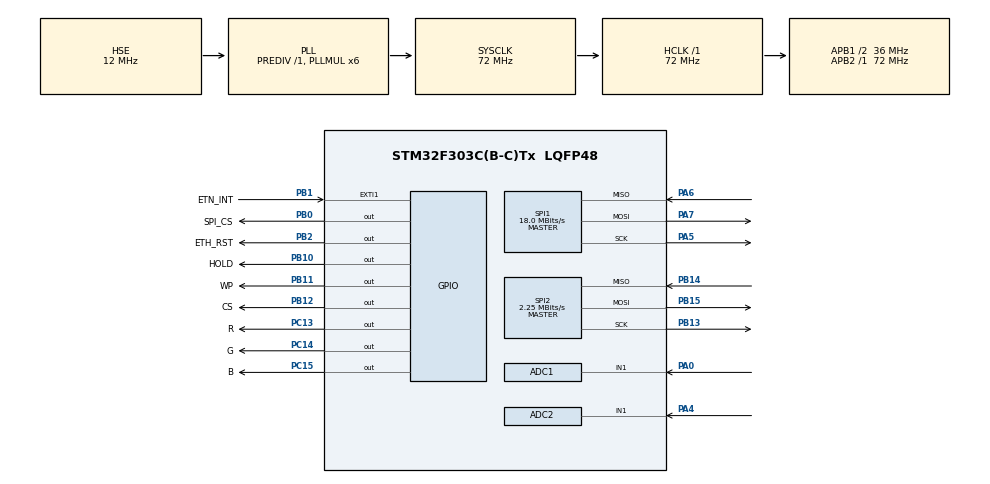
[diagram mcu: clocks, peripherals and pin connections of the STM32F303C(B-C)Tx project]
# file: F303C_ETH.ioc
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ADC1.Channel-0\#ChannelRegularConversion=ADC_CHANNEL_1
ADC1.ClockPrescaler=ADC_CLOCK_SYNC_PCLK_DIV2
ADC1.ContinuousConvMode=DISABLE
ADC1.DMAContinuousRequests=ENABLE
ADC1.ExternalTrigConv=ADC_EXTERNALTRIGCONV_T3_TRGO
ADC1.NbrOfConversionFlag=1
ADC1.Offset-0\#ChannelRegularConversion=0
ADC1.OffsetNumber-0\#ChannelRegularConversion=ADC_OFFSET_NONE
ADC1.Rank-0\#ChannelRegularConversion=1
ADC1.SamplingTime-0\#ChannelRegularConversion=ADC_SAMPLETIME_61CYCLES_5
ADC1.master=1
ADC2.Channel-0\#ChannelRegularConversion=ADC_CHANNEL_1
ADC2.ClockPrescaler=ADC_CLOCK_SYNC_PCLK_DIV2
ADC2.NbrOfConversionFlag=1
ADC2.Offset-0\#ChannelRegularConversion=0
ADC2.OffsetNumber-0\#ChannelRegularConversion=ADC_OFFSET_NONE
ADC2.Rank-0\#ChannelRegularConversion=1
ADC2.SamplingTime-0\#ChannelRegularConversion=ADC_SAMPLETIME_1CYCLE_5
Dma.ADC1.0.Direction=DMA_PERIPH_TO_MEMORY
Dma.ADC1.0.Instance=DMA1_Channel1
Dma.ADC1.0.MemDataAlignment=DMA_MDATAALIGN_HALFWORD
Dma.ADC1.0.MemInc=DMA_MINC_ENABLE
Dma.ADC1.0.Mode=DMA_CIRCULAR
Dma.ADC1.0.PeriphDataAlignment=DMA_PDATAALIGN_HALFWORD
Dma.ADC1.0.PeriphInc=DMA_PINC_DISABLE
Dma.ADC1.0.Priority=DMA_PRIORITY_LOW
Dma.Request0=ADC1
FREERTOS.BinarySemaphores01=ADC_end,Dynamic,NULL
FREERTOS.Tasks01=MainTask,0,256,mainTask,Default,NULL,Dynamic,NULL,NULL;LED,0,256,led,Default,NULL,Dynamic,NULL,NULL
FREERTOS.configTOTAL_HEAP_SIZE=10072
Mcu.Family=STM32F3
Mcu.Name=STM32F303C(B-C)Tx
Mcu.Package=LQFP48
NVIC.DMA1_Channel1_IRQn=true\:5\:0\:false\:false\:true\:true\:false\:true\:true
NVIC.PriorityGroup=NVIC_PRIORITYGROUP_4
NVIC.TIM6_DAC_IRQn=true\:5\:0\:false\:false\:true\:true\:true\:true\:true
NVIC.TIM7_IRQn=true\:0\:0\:false\:false\:true\:false\:false\:true\:true
NVIC.TimeBase=TIM7_IRQn
NVIC.TimeBaseIP=TIM7
PA0.Mode=IN1-Single-Ended
PA0.Signal=ADC1_IN1
PA13.Mode=Serial_Wire
PA13.Signal=SYS_JTMS-SWDIO
PA14.Mode=Serial_Wire
PA14.Signal=SYS_JTCK-SWCLK
PA4.Mode=IN1-Single-Ended
PA4.Signal=ADC2_IN1
PA5.Mode=Full_Duplex_Master
PA5.Signal=SPI1_SCK
PA6.Mode=Full_Duplex_Master
PA6.Signal=SPI1_MISO
PA7.Mode=Full_Duplex_Master
PA7.Signal=SPI1_MOSI
PB0.GPIO_Label=SPI_CS
PB0.Signal=GPIO_Output
PB1.GPIO_Label=ETN_INT
PB1.Signal=GPXTI1
PB10.GPIO_Label=HOLD
PB10.Signal=GPIO_Output
PB11.GPIO_Label=WP
PB11.Signal=GPIO_Output
PB12.GPIO_Label=CS
PB12.Signal=GPIO_Output
PB13.Mode=Full_Duplex_Master
PB13.Signal=SPI2_SCK
PB14.Mode=Full_Duplex_Master
PB14.Signal=SPI2_MISO
PB15.Mode=Full_Duplex_Master
PB15.Signal=SPI2_MOSI
PB2.GPIO_Label=ETH_RST
PB2.Signal=GPIO_Output
PC13.GPIO_Label=R
PC13.Signal=GPIO_Output
PC14-OSC32_IN.GPIO_Label=G
PC14-OSC32_IN.Signal=GPIO_Output
PC15-OSC32_OUT.GPIO_Label=B
PC15-OSC32_OUT.Signal=GPIO_Output
PF0-OSC_IN.Mode=HSE-External-Oscillator
PF0-OSC_IN.Signal=RCC_OSC_IN
PF1-OSC_OUT.Mode=HSE-External-Oscillator
PF1-OSC_OUT.Signal=RCC_OSC_OUT
ProjectManager.HeapSize=0x1770
ProjectManager.StackSize=0x2710
ProjectManager.TargetToolchain=STM32CubeIDE
RCC.AHBFreq_Value=72000000
RCC.APB1CLKDivider=RCC_HCLK_DIV2
RCC.APB1Freq_Value=36000000
RCC.APB1TimFreq_Value=72000000
RCC.APB2Freq_Value=72000000
RCC.APB2TimFreq_Value=72000000
RCC.CortexFreq_Value=72000000
RCC.HCLKFreq_Value=72000000
RCC.HSE_VALUE=12000000
RCC.HSI_VALUE=8000000
RCC.LSE_VALUE=32768
RCC.PLLMUL=RCC_PLL_MUL6
RCC.PLLSourceVirtual=RCC_PLLSOURCE_HSE
RCC.SYSCLKFreq_VALUE=72000000
RCC.SYSCLKSourceVirtual=RCC_SYSCLKSOURCE_PLLCLK
RCC.USBFreq_Value=72000000
SPI1.BaudRatePrescaler=SPI_BAUDRATEPRESCALER_4
SPI1.CalculateBaudRate=18.0 MBits/s
SPI1.DataSize=SPI_DATASIZE_8BIT
SPI1.Direction=SPI_DIRECTION_2LINES
SPI1.Mode=SPI_MODE_MASTER
SPI1.VirtualType=VM_MASTER
SPI2.BaudRatePrescaler=SPI_BAUDRATEPRESCALER_16
SPI2.CalculateBaudRate=2.25 MBits/s
SPI2.DataSize=SPI_DATASIZE_8BIT
SPI2.Direction=SPI_DIRECTION_2LINES
SPI2.Mode=SPI_MODE_MASTER
SPI2.VirtualType=VM_MASTER
TIM3.Channel-Output\ Compare1\ No\ Output=TIM_CHANNEL_1
TIM3.Period=1000-1
TIM3.Prescaler=72-1
TIM3.TIM_MasterOutputTrigger=TIM_TRGO_UPDATE
TIM6.Prescaler=72-1
VP_FREERTOS_VS_CMSIS_V1.Mode=CMSIS_V1
VP_SYS_VS_tim7.Mode=TIM7
VP_TIM3_VS_no_output1.Mode=Output Compare1 No Output
VP_TIM6_VS_ClockSourceINT.Mode=Enable_Timer
board=custom

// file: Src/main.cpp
/* USER CODE BEGIN Header */
/**
  ******************************************************************************
  * @file           : main.c
  * @brief          : Main program body
  ******************************************************************************
  * @attention
  *
  * Copyright (c) 2022 STMicroelectronics.
  * All rights reserved.
  *
  * This software is licensed under terms that can be found in the LICENSE file
  * in the root directory of this software component.
  * If no LICENSE file comes with this software, it is provided AS-IS.
  *
  ******************************************************************************
  */
/* USER CODE END Header */
#include "main.h"
#include "cmsis_os.h"
#include "adc.h"
#include "dma.h"
#include "spi.h"
#include "tim.h"
#include "gpio.h"

/* USER CODE BEGIN Includes */
#include "flash_spi.h"
#include "Delay_us_DWT.h"
#include "LED.h"
/* USER CODE END Includes */

/* USER CODE BEGIN PV */
settings_t settings = {115200, 0x0E};

uint32_t count_tic = 0; //для замеров времени выполнения кода
extern TIM_HandleTypeDef htim3;

led LED_IPadr;
led LED_error;
led LED_OSstart;

/* USER CODE END PV */

void SystemClock_Config(void);
void MX_FREERTOS_Init(void);

int main(void)
{

  /* MCU Configuration--------------------------------------------------------*/

  /* Reset of all peripherals, Initializes the Flash interface and the Systick. */
  HAL_Init();

  /* Configure the system clock */
  SystemClock_Config();

  /* Initialize all configured peripherals */
  MX_GPIO_Init();
  MX_DMA_Init();
  MX_ADC1_Init();
  MX_ADC2_Init();
  MX_SPI2_Init();
  MX_TIM3_Init();
  MX_TIM6_Init();
  MX_SPI1_Init();

  /* Call init function for freertos objects (in freertos.c) */
  MX_FREERTOS_Init();

  /* Start scheduler */
  osKernelStart();

  /* We should never get here as control is now taken by the scheduler */
  /* Infinite loop */
  while (1)
  {

  }
}

void SystemClock_Config(void)
{
  RCC_OscInitTypeDef RCC_OscInitStruct = {0};
  RCC_ClkInitTypeDef RCC_ClkInitStruct = {0};

  /** Initializes the RCC Oscillators according to the specified parameters
  * in the RCC_OscInitTypeDef structure.
  */
  RCC_OscInitStruct.OscillatorType = RCC_OSCILLATORTYPE_HSE;
  RCC_OscInitStruct.HSEState = RCC_HSE_ON;
  RCC_OscInitStruct.HSEPredivValue = RCC_HSE_PREDIV_DIV1;
  RCC_OscInitStruct.HSIState = RCC_HSI_ON;
  RCC_OscInitStruct.PLL.PLLState = RCC_PLL_ON;
  RCC_OscInitStruct.PLL.PLLSource = RCC_PLLSOURCE_HSE;
  RCC_OscInitStruct.PLL.PLLMUL = RCC_PLL_MUL6;
  if (HAL_RCC_OscConfig(&RCC_OscInitStruct) != HAL_OK)
  {
    Error_Handler();
  }

  /** Initializes the CPU, AHB and APB buses clocks
  */
  RCC_ClkInitStruct.ClockType = RCC_CLOCKTYPE_HCLK|RCC_CLOCKTYPE_SYSCLK
                              |RCC_CLOCKTYPE_PCLK1|RCC_CLOCKTYPE_PCLK2;
  RCC_ClkInitStruct.SYSCLKSource = RCC_SYSCLKSOURCE_PLLCLK;
  RCC_ClkInitStruct.AHBCLKDivider = RCC_SYSCLK_DIV1;
  RCC_ClkInitStruct.APB1CLKDivider = RCC_HCLK_DIV2;
  RCC_ClkInitStruct.APB2CLKDivider = RCC_HCLK_DIV1;

  if (HAL_RCC_ClockConfig(&RCC_ClkInitStruct, FLASH_LATENCY_2) != HAL_OK)
  {
    Error_Handler();
  }
}

void HAL_TIM_PeriodElapsedCallback(TIM_HandleTypeDef *htim)
{
  if (htim->Instance == TIM7) {
    HAL_IncTick();
  }
}

void Error_Handler(void)
{
  __disable_irq();
  while (1)
  {
  }
}
